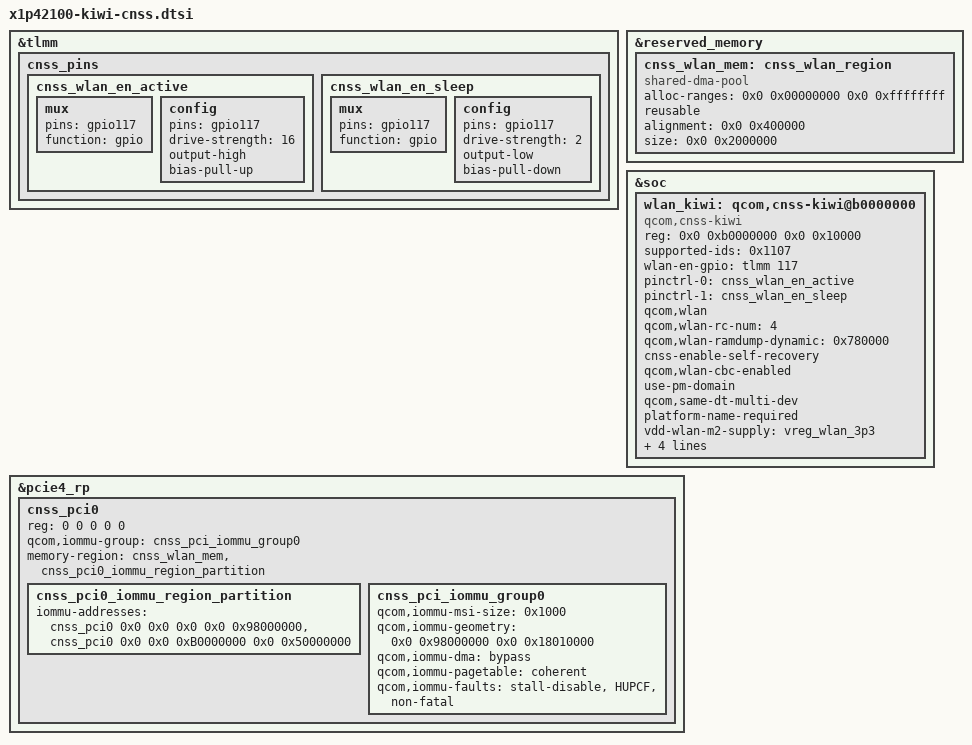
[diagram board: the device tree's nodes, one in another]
// SPDX-License-Identifier: BSD-3-Clause

/*
 * Copyright (c) Qualcomm Technologies, Inc. and/or its subsidiaries.
 */

#include <dt-bindings/interconnect/qcom,x1p42100.h>

&tlmm {
	cnss_pins {
		cnss_wlan_en_active: cnss_wlan_en_active {
			mux {
				pins = "gpio117";
				function = "gpio";
			};

			config {
				pins = "gpio117";
				drive-strength = <16>;
				output-high;
				bias-pull-up;
			};
		};

		cnss_wlan_en_sleep: cnss_wlan_en_sleep {
			mux {
				pins = "gpio117";
				function = "gpio";
			};

			config {
				pins = "gpio117";
				drive-strength = <2>;
				output-low;
				bias-pull-down;
			};
		};
	};
};

&reserved_memory {
	cnss_wlan_mem: cnss_wlan_region {
		compatible = "shared-dma-pool";
		alloc-ranges = <0x0 0x00000000 0x0 0xffffffff>;
		reusable;
		alignment = <0x0 0x400000>;
		size = <0x0 0x2000000>;
	};
};

&soc {
	wlan_kiwi: qcom,cnss-kiwi@b0000000 {
		compatible = "qcom,cnss-kiwi";
		reg = <0x0 0xb0000000 0x0 0x10000>;
		reg-names = "smmu_iova_ipa";

		supported-ids = <0x1107>;
		wlan-en-gpio = <&tlmm 117 0>;
		pinctrl-names = "wlan_en_active", "wlan_en_sleep";
		pinctrl-0 = <&cnss_wlan_en_active>;
		pinctrl-1 = <&cnss_wlan_en_sleep>;

		qcom,wlan;
		qcom,wlan-rc-num = <4>;
		qcom,wlan-ramdump-dynamic = <0x780000>;
		cnss-enable-self-recovery;
		qcom,wlan-cbc-enabled;
		use-pm-domain;
		qcom,same-dt-multi-dev;
		platform-name-required;

		vdd-wlan-m2-supply = <&vreg_wlan_3p3>;
		qcom,vdd-wlan-m2-config = <3300000 3300000 0 0 0>;
		vdd-wlan-io-supply = <&L15B>;
		qcom,vdd-wlan-io-config = <1800000 1800000 0 0 0>;

		/* cpu mask used for wlan tx rx interrupt affinity
		 * <cpumask_for_rx_interrupts cpumask_for_tx_comp_interrupts>
		 */
		wlan-txrx-intr-cpumask = <0x3 0x30>;
	};
};

&pcie4_rp {
	cnss_pci0: cnss_pci0 {
		reg = <0 0 0 0 0>;
		qcom,iommu-group = <&cnss_pci_iommu_group0>;
		memory-region =
			<&cnss_wlan_mem &cnss_pci0_iommu_region_partition>;

		#address-cells = <2>;
		#size-cells = <2>;

		cnss_pci0_iommu_region_partition: cnss_pci0_iommu_region_partition {
			/* address-cells =3 size-cells=2 from canoe-pcie.dtsi */
			iommu-addresses = <&cnss_pci0 0x0 0x0 0x0 0x0 0x98000000>,
					  <&cnss_pci0 0x0 0x0 0xB0000000 0x0 0x50000000>;
		};

		cnss_pci_iommu_group0: cnss_pci_iommu_group0 {
			qcom,iommu-msi-size = <0x1000>;
			qcom,iommu-geometry = <0x0 0x98000000 0x0 0x18010000>;
			/* bypass due to SMMU V3 is NOT well supported yet */
			qcom,iommu-dma = "bypass";
			qcom,iommu-pagetable = "coherent";
			qcom,iommu-faults = "stall-disable", "HUPCF",
					    "non-fatal";
		};
	};
};
